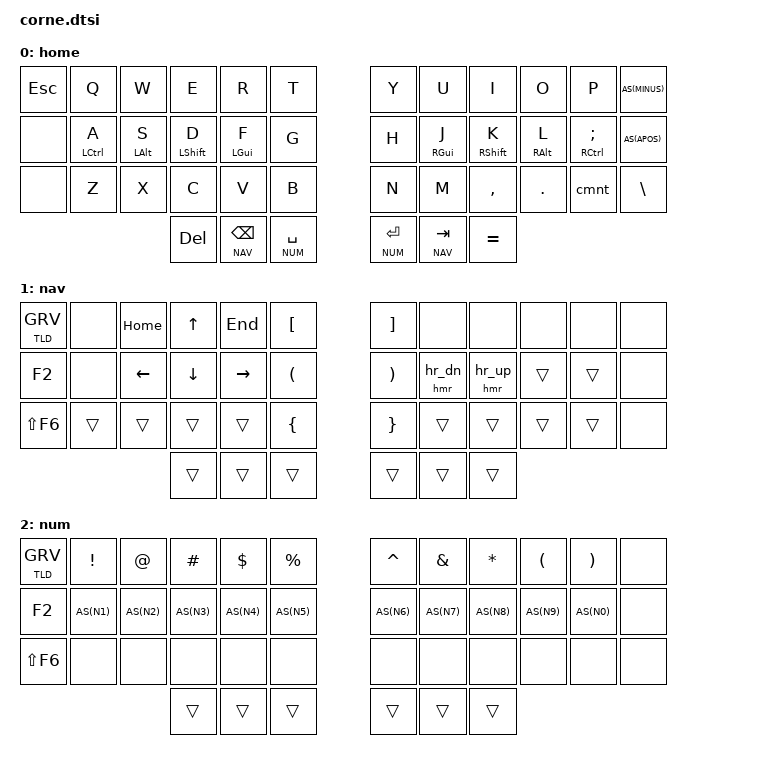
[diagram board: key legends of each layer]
#include <behaviors.dtsi>
#include <dt-bindings/zmk/keys.h>
#include <dt-bindings/zmk/bt.h>
#include "../zmk-nodefree-config/helper.h"
#include "../zmk-nodefree-config/keypos_def/keypos_42keys.h"

/* layer and key shortcuts */
#define ___ &trans
#define DEF 0
#define NAV 1
#define NUM 2
#define TLD TILDE
#define GRV GRAVE
#define hr_dn RGUI PG_DN
#define hr_up RSHIFT PG_UP
#define AS(keycode) &as LS(keycode) keycode // Autoshift Macro
#define KEYS_L LT0 LT1 LT2 LT3 LT4 LT5 LM0 LM1 LM2 LM3 LM4 LM5 LB0 LB1 LB2 LB3 LB4 LB5  // left-hand keys
#define KEYS_R RT0 RT1 RT2 RT3 RT4 RT5 RM0 RM1 RM2 RM3 RM4 RM5 RB0 RB1 RB2 RB3 RB4 RB5  // right-hand keys
#define THUMBS LH2 LH1 LH0 RH0 RH1 RH2                                                  // thumb keys

/* custom behaviors */

// homerow mod left
ZMK_BEHAVIOR(hml, hold_tap,
flavor = "balanced";
tapping-term-ms = <200>;
quick-tap-ms = <165>;                // repeat on tap-into-hold
require-prior-idle-ms = <150>;
bindings = <&kp>, <&kp>;
hold-trigger-key-positions = <KEYS_R THUMBS>;
hold-trigger-on-release;             // delay positional check until key-release
)

// homerow mod right
ZMK_BEHAVIOR(hmr, hold_tap,
flavor = "balanced";
tapping-term-ms = <200>;
quick-tap-ms = <165>;                // repeat on tap-into-hold
require-prior-idle-ms = <150>;
bindings = <&kp>, <&kp>;
hold-trigger-key-positions = <KEYS_L THUMBS>;
hold-trigger-on-release;             // delay positional check until key-release
)

// auto-shift
ZMK_BEHAVIOR(as, hold_tap,
flavor = "tap-preferred";
tapping-term-ms = <175>;
quick-tap-ms = <0>;
bindings = <&kp>, <&kp>;
)

// layer toggle w/ repeat
ZMK_BEHAVIOR(lt_rpt, layer_tap,
flavor = "tap-preferred";
tapping-term-ms = <175>;
quick-tap-ms = <0>;
bindings = <&kp>, <&kp>;
)

// comment tap: / | double-tap:
ZMK_BEHAVIOR(cmnt, tap_dance,
tapping-term-ms = <200>;
bindings = <&kp FSLH>, <&kp RG(SLASH)>;
)

ZMK_BEHAVIOR(col_eq, macro,
wait-ms = <100>;
tap-ms = <5>;
bindings = <&kp COLON &kp EQUAL>;
)

// combos
ZMK_COMBO(go_eq,  &col_eq, RH1 RH2, DEF)
ZMK_COMBO(caps_word, &caps_word, LT0 RT0, NUM)
ZMK_COMBO(screen_cap, &kp LS(LG(NUMBER_4)), LT5 RT4, DEF)
ZMK_COMBO(copy,  &kp LG(C), LM3 LM2, ALL)
ZMK_COMBO(paste, &kp LG(V), LM2 LM1, ALL)
ZMK_COMBO(bt_windows, &bt BT_SEL 0, RT3 RT4 RT5, ALL)
ZMK_COMBO(bt_mac, &bt BT_SEL 1, RM3 RM4 RM5, ALL)
ZMK_COMBO(bt_clear, &bt BT_CLR, RB3 RB4 RB5, ALL)

/* keymap */

ZMK_LAYER(home,
// ╭─────────────┬─────────────┬─────────────┬─────────────┬─────────────┬─────────────╮   ╭─────────────┬─────────────┬─────────────┬─────────────┬─────────────┬─────────────╮
    &kp ESC       &kp Q         &kp W         &kp E         &kp R         &kp T             &kp Y         &kp U         &kp I         &kp O         &kp P         AS(MINUS)
// ├─────────────┼─────────────┼─────────────┼─────────────┼─────────────┼─────────────┤   ├─────────────┼─────────────┼─────────────┼─────────────┼─────────────┼─────────────┤
    &none         &hml LCTRL A  &hml LALT S   &hml LSHIFT D &hml LGUI F   &kp G             &kp H         &hmr RGUI J   &hmr RSHIFT K &hmr RALT L   &hmr RCTRL SEMI AS(APOS)
// ├─────────────┼─────────────┼─────────────┼─────────────┼─────────────┼─────────────┤   ├─────────────┼─────────────┼─────────────┼─────────────┼─────────────┤─────────────┤
    &none         &kp Z         &kp X         &kp C         &kp V         &kp B             &kp N         &kp M         &kp COMMA     &kp DOT       &cmnt      &kp BSLH
// ╰─────────────┼─────────────┼─────────────┼─────────────┼─────────────┼─────────────┤   ├─────────────├─────────────┼─────────────┼─────────────┼─────────────┼─────────────┤
                                              &kp DEL       &lt NAV BSPC  &lt NUM SPACE     &lt NUM RET   &lt NAV TAB   &kp EQUAL
//                                           ╰─────────────┴─────────────┴─────────────╯   ╰─────────────┴─────────────┴─────────────╯
)

ZMK_LAYER(nav,
// ╭─────────────┬─────────────┬─────────────┬─────────────┬─────────────┬─────────────╮   ╭─────────────┬─────────────┬─────────────┬─────────────┬─────────────┬─────────────╮
    &mt TLD GRV   &none         &kp HOME      &kp UP        &kp END       &kp LBKT          &kp RBKT      &none         &none         &none         &none         &none
// ├─────────────┼─────────────┼─────────────┼─────────────┼─────────────┼─────────────┤   ├─────────────┼─────────────┼─────────────┼─────────────┼─────────────┼─────────────┤
    &kp F2        &none         &kp LEFT      &kp DOWN      &kp RIGHT     &kp LPAR          &kp RPAR      &hmr hr_dn    &hmr hr_up    &trans        &trans        &none
// ├─────────────┼─────────────┼─────────────┼─────────────┼─────────────┼─────────────┤   ├─────────────┼─────────────┼─────────────┼─────────────┼─────────────┼─────────────┤
    &kp LS(F6)    &trans        &trans        &trans        &trans        &kp LBRC          &kp RBRC      &trans        &trans        &trans        &trans        &none
// ╰─────────────┼─────────────┼─────────────┼─────────────┼─────────────┼─────────────┤   ├─────────────├─────────────┼─────────────┼─────────────┼─────────────┼─────────────┤
                                              ___           ___           ___               ___           ___           ___
//                                           ╰─────────────┴─────────────┴─────────────╯   ╰─────────────┴─────────────┴─────────────╯
)

ZMK_LAYER(num,
// ╭─────────────┬─────────────┬─────────────┬─────────────┬─────────────┬─────────────╮   ╭─────────────┬─────────────┬─────────────┬─────────────┬─────────────┬─────────────╮
    &mt TLD GRV   &kp EXCL      &kp AT        &kp HASH      &kp DLLR      &kp PRCNT         &kp CARET     &kp AMPS      &kp STAR      &kp LPAR      &kp RPAR      &none
// ├─────────────┼─────────────┼─────────────┼─────────────┼─────────────┼─────────────┤   ├─────────────┼─────────────┼─────────────┼─────────────┼─────────────┼─────────────┤
    &kp F2        AS(N1)        AS(N2)        AS(N3)        AS(N4)        AS(N5)            AS(N6)        AS(N7)        AS(N8)        AS(N9)        AS(N0)        &none
// ├─────────────┼─────────────┼─────────────┼─────────────┼─────────────┼─────────────┤   ├─────────────┼─────────────┼─────────────┼─────────────┼─────────────┤─────────────┤
    &kp LS(F6)    &none         &none         &none         &none         &none             &none         &none         &none         &none         &none         &none
// ╰─────────────┼─────────────┼─────────────┼─────────────┼─────────────┼─────────────┤   ├─────────────├─────────────┼─────────────┼─────────────┼─────────────┼─────────────┤
                                              ___           ___           ___               ___           ___           ___
//                                           ╰─────────────┴─────────────┴─────────────╯   ╰─────────────┴─────────────┴─────────────╯
)
